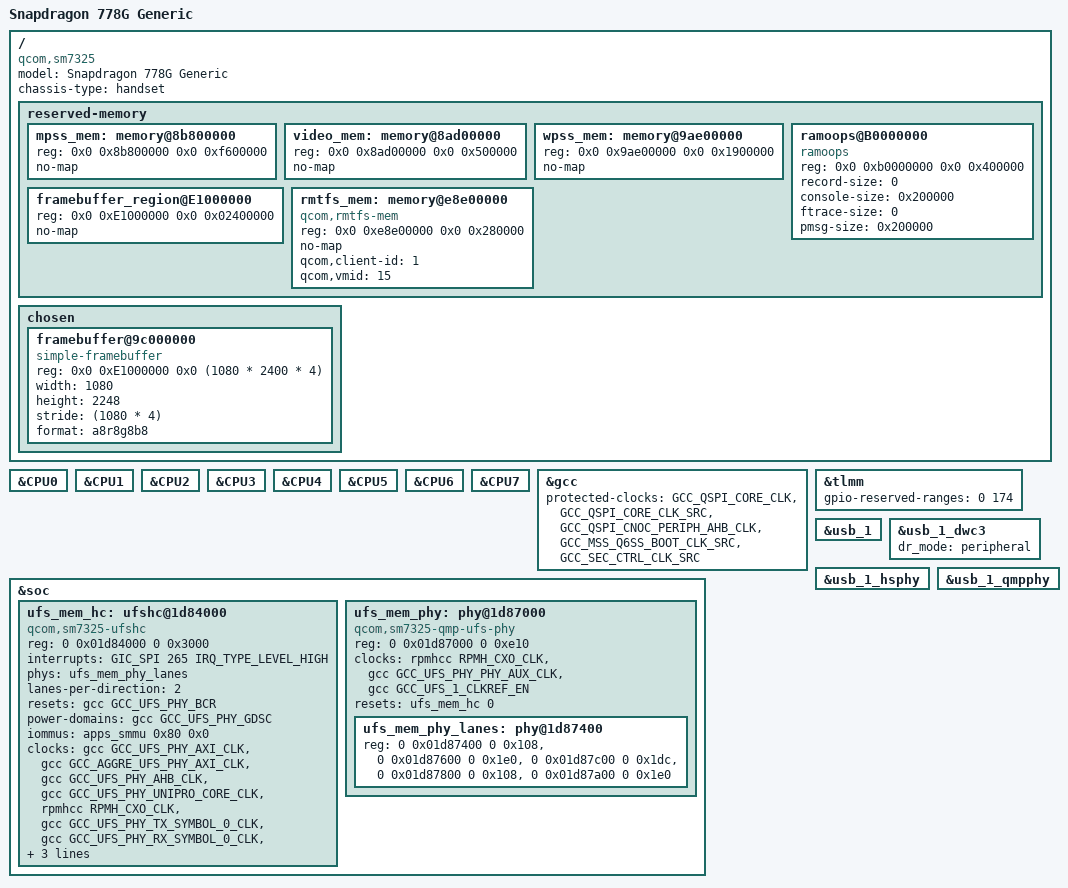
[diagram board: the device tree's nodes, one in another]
// SPDX-License-Identifier: BSD-3-Clause
/*
 * Copyright (c) 2022, Xilin Wu <strongtz@yeah.net>
 */

/dts-v1/;

#include <dt-bindings/gpio/gpio.h>
#include <dt-bindings/regulator/qcom,rpmh-regulator.h>

#include "sc7280.dtsi"

/delete-node/ &video_mem;
/delete-node/ &rmtfs_mem;

/ {
	model = "Snapdragon 778G Generic";
	compatible = "qcom,sm7325", "qcom,sc7280";
	chassis-type = "handset";
	
	reserved-memory {
		#address-cells = <2>;
		#size-cells = <2>;
		ranges;

		mpss_mem: memory@8b800000 {
			reg = <0x0 0x8b800000 0x0 0xf600000>;
			no-map;
		};

		video_mem: memory@8ad00000 {
			reg = <0x0 0x8ad00000 0x0 0x500000>;
			no-map;
		};

		wpss_mem: memory@9ae00000 {
			reg = <0x0 0x9ae00000 0x0 0x1900000>;
			no-map;
		};

		ramoops@B0000000 {
			compatible = "ramoops";
			reg = <0x0 0xb0000000 0x0 0x400000>;
			record-size = <0>;
			console-size = <0x200000>;
			ftrace-size = <0>;
			pmsg-size = <0x200000>;
		};

		framebuffer_region@E1000000 {
			reg = <0x0 0xE1000000 0x0 0x02400000>;
			no-map;
		};

		rmtfs_mem: memory@e8e00000 {
			compatible = "qcom,rmtfs-mem";
			reg = <0x0 0xe8e00000 0x0 0x280000>;
			no-map;

			qcom,client-id = <1>;
			qcom,vmid = <15>;
		};
	};

	chosen {
		#address-cells = <2>;
		#size-cells = <2>;
		ranges;
		framebuffer@9c000000 {
			compatible = "simple-framebuffer";
			reg = <0x0 0xE1000000 0x0 (1080 * 2400 * 4)>;
			width = <1080>;
			height = <2248>;
			stride = <(1080 * 4)>;
			format = "a8r8g8b8";
		};
	};
};

&CPU0 {
	/delete-property/ operating-points-v2;
};

&CPU1 {
	/delete-property/ operating-points-v2;
};

&CPU2 {
	/delete-property/ operating-points-v2;
};

&CPU3 {
	/delete-property/ operating-points-v2;
};

&CPU4 {
	/delete-property/ operating-points-v2;
};

&CPU5 {
	/delete-property/ operating-points-v2;
};

&CPU6 {
	/delete-property/ operating-points-v2;
};

&CPU7 {
	/delete-property/ operating-points-v2;
};

&gcc {
	protected-clocks = <GCC_QSPI_CORE_CLK>,
			   <GCC_QSPI_CORE_CLK_SRC>,
			   <GCC_QSPI_CNOC_PERIPH_AHB_CLK>,
               <GCC_MSS_Q6SS_BOOT_CLK_SRC>,
               <GCC_SEC_CTRL_CLK_SRC>;
};

// SC7280 doesn't have UFS yet.
&soc {
    ufs_mem_hc: ufshc@1d84000 {
        compatible = "qcom,sm7325-ufshc", "qcom,ufshc",
                    "jedec,ufs-2.0";
        reg = <0 0x01d84000 0 0x3000>;
        interrupts = <GIC_SPI 265 IRQ_TYPE_LEVEL_HIGH>;
        phys = <&ufs_mem_phy_lanes>;
        phy-names = "ufsphy";
        lanes-per-direction = <2>;
        #reset-cells = <1>;
        resets = <&gcc GCC_UFS_PHY_BCR>;
        reset-names = "rst";

        power-domains = <&gcc GCC_UFS_PHY_GDSC>;

        iommus = <&apps_smmu 0x80 0x0>;

        clock-names =
            "core_clk",
            "bus_aggr_clk",
            "iface_clk",
            "core_clk_unipro",
            "ref_clk",
            "tx_lane0_sync_clk",
            "rx_lane0_sync_clk",
            "rx_lane1_sync_clk";
        clocks =
            <&gcc GCC_UFS_PHY_AXI_CLK>,
            <&gcc GCC_AGGRE_UFS_PHY_AXI_CLK>,
            <&gcc GCC_UFS_PHY_AHB_CLK>,
            <&gcc GCC_UFS_PHY_UNIPRO_CORE_CLK>,
            <&rpmhcc RPMH_CXO_CLK>,
            <&gcc GCC_UFS_PHY_TX_SYMBOL_0_CLK>,
            <&gcc GCC_UFS_PHY_RX_SYMBOL_0_CLK>,
            <&gcc GCC_UFS_PHY_RX_SYMBOL_1_CLK>;
        freq-table-hz =
            <75000000 300000000>,
            <0 0>,
            <0 0>,
            <75000000 300000000>,
            <0 0>,
            <0 0>,
            <0 0>,
            <0 0>;
        status = "okay";
    };

    ufs_mem_phy: phy@1d87000 {
        compatible = "qcom,sm7325-qmp-ufs-phy";
        reg = <0 0x01d87000 0 0xe10>;
        #address-cells = <2>;
        #size-cells = <2>;
        ranges;
        clock-names = "ref", "ref_aux", "qref";
        clocks = <&rpmhcc RPMH_CXO_CLK>,
                <&gcc GCC_UFS_PHY_PHY_AUX_CLK>,
                <&gcc GCC_UFS_1_CLKREF_EN>;

        resets = <&ufs_mem_hc 0>;
        reset-names = "ufsphy";
        status = "okay";

        ufs_mem_phy_lanes: phy@1d87400 {
            reg = <0 0x01d87400 0 0x108>,
                    <0 0x01d87600 0 0x1e0>,
                    <0 0x01d87c00 0 0x1dc>,
                    <0 0x01d87800 0 0x108>,
                    <0 0x01d87a00 0 0x1e0>;
            #phy-cells = <0>;
        };
    };
};

&tlmm {
    // Reserve all
	gpio-reserved-ranges = <0 174>;
};

&usb_1 {
	status = "okay";
};

&usb_1_dwc3 {
	dr_mode = "peripheral";
};

&usb_1_hsphy {
	status = "okay";
	// vdd-supply = <&vreg_l4a>;
	// vdda-pll-supply = <&vreg_l11a>;
	// vdda-phy-dpdm-supply = <&vreg_l17a>;
};

&usb_1_qmpphy {
	status = "okay";
	// vdda-phy-supply = <&vreg_l4a>;
	// vdda-pll-supply = <&vreg_l3c>;
};
